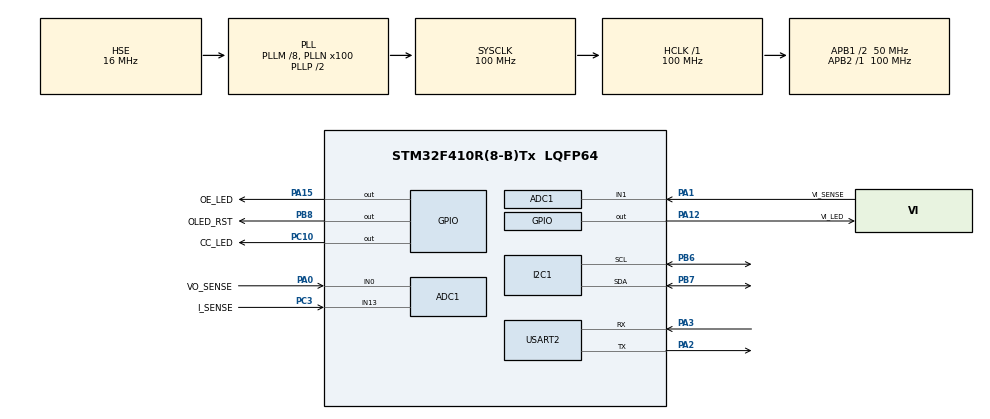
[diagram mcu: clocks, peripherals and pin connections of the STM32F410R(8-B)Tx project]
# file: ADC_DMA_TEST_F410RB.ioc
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Mcu.Family=STM32F4
VP_SYS_VS_tim6.Mode=TIM6
RCC.CortexFreq_Value=100000000
NVIC.TIM6_DAC_IRQn=true\:0\:0\:false\:false\:true\:false\:true
PC10.Signal=GPIO_Output
RCC.SYSCLKSource=RCC_SYSCLKSOURCE_PLLCLK
ProjectManager.StackSize=0x400
PA15.GPIO_Label=OE_LED
PA12.Signal=GPIO_Output
PH0\ -\ OSC_IN.Signal=RCC_OSC_IN
RCC.HCLKFreq_Value=100000000
RCC.APB2TimFreq_Value=100000000
PB6.Signal=I2C1_SCL
Dma.ADC1.0.Direction=DMA_PERIPH_TO_MEMORY
ADC1.Channel-2\#ChannelRegularConversion=ADC_CHANNEL_1
PB6.Mode=I2C
PC3.Signal=SharedAnalog_PC3
NVIC.DMA2_Stream0_IRQn=true\:0\:0\:false\:false\:true\:false\:true
Dma.ADC1.0.MemDataAlignment=DMA_MDATAALIGN_HALFWORD
RCC.AHBFreq_Value=100000000
ADC1.Channel-0\#ChannelRegularConversion=ADC_CHANNEL_13
RCC.HSE_VALUE=16000000
PB3.Mode=Trace_Asynchronous_SW
ADC1.Rank-2\#ChannelRegularConversion=3
PA14.Mode=Trace_Asynchronous_SW
Dma.ADC1.0.PeriphInc=DMA_PINC_DISABLE
PB8.PinState=GPIO_PIN_RESET
PB7.Signal=I2C1_SDA
ADC1.SamplingTime-0\#ChannelRegularConversion=ADC_SAMPLETIME_3CYCLES
Mcu.Package=LQFP64
NVIC.TimeBase=TIM6_DAC_IRQn
USART2.VirtualMode=VM_ASYNC
RCC.EnbaleCSS=true
NVIC.TimeBaseIP=TIM6
PA15.Signal=GPIO_Output
RCC.APB1TimFreq_Value=100000000
Dma.ADC1.0.FIFOMode=DMA_FIFOMODE_DISABLE
Dma.Request0=ADC1
ADC1.EOCSelection=ADC_EOC_SEQ_CONV
PA3.Signal=USART2_RX
RCC.PLLSourceVirtual=RCC_PLLSOURCE_HSE
Dma.ADC1.0.Instance=DMA2_Stream0
ADC1.Rank-0\#ChannelRegularConversion=1
PC10.GPIO_Label=CC_LED
SH.SharedAnalog_PC3.1=ADC1_IN13,IN13
SH.SharedAnalog_PA0.0=GPIO_Analog
SH.SharedAnalog_PC3.0=GPIO_Analog
SH.SharedAnalog_PA0.1=ADC1_IN0,IN0
PH1\ -\ OSC_OUT.Mode=HSE-External-Oscillator
TIM11.Prescaler=8400-1
RCC.APB1CLKDivider=RCC_HCLK_DIV2
PA12.GPIO_Label=VI_LED
ADC1.SamplingTime-2\#ChannelRegularConversion=ADC_SAMPLETIME_3CYCLES
PA0-WKUP.GPIO_Label=VO_SENSE
PA0-WKUP.Signal=SharedAnalog_PA0
VP_TIM11_VS_ClockSourceINT.Mode=Enable_Timer
PA13.Signal=SYS_JTMS-SWDIO
PA3.Mode=Asynchronous
PB8.GPIO_Label=OLED_RST
Dma.ADC1.0.PeriphDataAlignment=DMA_PDATAALIGN_HALFWORD
PH0\ -\ OSC_IN.Mode=HSE-External-Oscillator
ProjectManager.TargetToolchain=STM32CubeIDE
Dma.ADC1.0.Mode=DMA_CIRCULAR
I2C1.I2C_Mode=I2C_Fast
Dma.ADC1.0.Priority=DMA_PRIORITY_HIGH
ADC1.Channel-1\#ChannelRegularConversion=ADC_CHANNEL_0
RCC.LSE_VALUE=32768
PA1.Signal=SharedAnalog_PA1
PH1\ -\ OSC_OUT.Signal=RCC_OSC_OUT
board=custom
RCC.VCOOutputFreq_Value=200000000
RCC.APB2Freq_Value=100000000
PA1.GPIO_Label=VI_SENSE
ADC1.DMAContinuousRequests=ENABLE
ADC1.NbrOfConversion=3
PA13.Mode=Trace_Asynchronous_SW
Mcu.Name=STM32F410R(8-B)Tx
PA2.Signal=USART2_TX
RCC.48MHZClocksFreq_Value=50000000
PB3.Signal=SYS_JTDO-SWO
ADC1.SamplingTime-1\#ChannelRegularConversion=ADC_SAMPLETIME_3CYCLES
RCC.SYSCLKFreq_VALUE=100000000
ADC1.master=1
ADC1.Rank-1\#ChannelRegularConversion=2
PB7.Mode=I2C
PA14.Signal=SYS_JTCK-SWCLK
Dma.ADC1.0.MemInc=DMA_MINC_ENABLE
ProjectManager.HeapSize=0x200
RCC.HSI_VALUE=16000000
SH.SharedAnalog_PA1.1=ADC1_IN1,IN1
NVIC.PriorityGroup=NVIC_PRIORITYGROUP_4
SH.SharedAnalog_PA1.0=GPIO_Analog
ADC1.NbrOfConversionFlag=1
RCC.PLLM=8
RCC.PLLN=100
PA2.Mode=Asynchronous
PB8.Signal=GPIO_Output
PC3.GPIO_Label=I_SENSE
RCC.APB1Freq_Value=50000000

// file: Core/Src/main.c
/* USER CODE BEGIN Header */
/**
  ******************************************************************************
  * @file           : main.c
  * @brief          : Main program body
  ******************************************************************************
  * @attention
  *
  * <h2><center>&copy; Copyright (c) 2021 STMicroelectronics.
  * All rights reserved.</center></h2>
  *
  * This software component is licensed by ST under Ultimate Liberty license
  * SLA0044, the "License"; You may not use this file except in compliance with
  * the License. You may obtain a copy of the License at:
  *                             www.st.com/SLA0044
  *
  ******************************************************************************
  */
/* USER CODE END Header */
#include "main.h"

ADC_HandleTypeDef hadc1;
DMA_HandleTypeDef hdma_adc1;

I2C_HandleTypeDef hi2c1;

TIM_HandleTypeDef htim11;

UART_HandleTypeDef huart2;

/* USER CODE BEGIN PV */
uint16_t buff[3];
/* USER CODE END PV */

void SystemClock_Config(void);
static void MX_GPIO_Init(void);
static void MX_DMA_Init(void);
static void MX_ADC1_Init(void);
static void MX_I2C1_Init(void);
static void MX_TIM11_Init(void);
static void MX_USART2_UART_Init(void);

int main(void)
{

  /* MCU Configuration--------------------------------------------------------*/

  /* Reset of all peripherals, Initializes the Flash interface and the Systick. */
  HAL_Init();

  /* Configure the system clock */
  SystemClock_Config();

  /* Initialize all configured peripherals */
  MX_GPIO_Init();
  MX_DMA_Init();
  MX_ADC1_Init();
  MX_I2C1_Init();
  MX_TIM11_Init();
  MX_USART2_UART_Init();
  /* USER CODE BEGIN 2 */
  HAL_ADC_Start_DMA(&hadc1, (uint32_t *)buff, 3);
  /* USER CODE END 2 */

  /* Infinite loop */
  while (1)
  {

  }
}

void SystemClock_Config(void)
{
  RCC_OscInitTypeDef RCC_OscInitStruct = {0};
  RCC_ClkInitTypeDef RCC_ClkInitStruct = {0};

  /** Configure the main internal regulator output voltage
  */
  __HAL_RCC_PWR_CLK_ENABLE();
  __HAL_PWR_VOLTAGESCALING_CONFIG(PWR_REGULATOR_VOLTAGE_SCALE1);
  /** Initializes the RCC Oscillators according to the specified parameters
  * in the RCC_OscInitTypeDef structure.
  */
  RCC_OscInitStruct.OscillatorType = RCC_OSCILLATORTYPE_HSE;
  RCC_OscInitStruct.HSEState = RCC_HSE_ON;
  RCC_OscInitStruct.PLL.PLLState = RCC_PLL_ON;
  RCC_OscInitStruct.PLL.PLLSource = RCC_PLLSOURCE_HSE;
  RCC_OscInitStruct.PLL.PLLM = 8;
  RCC_OscInitStruct.PLL.PLLN = 100;
  RCC_OscInitStruct.PLL.PLLP = RCC_PLLP_DIV2;
  RCC_OscInitStruct.PLL.PLLQ = 4;
  RCC_OscInitStruct.PLL.PLLR = 2;
  if (HAL_RCC_OscConfig(&RCC_OscInitStruct) != HAL_OK)
  {
    Error_Handler();
  }
  /** Initializes the CPU, AHB and APB buses clocks
  */
  RCC_ClkInitStruct.ClockType = RCC_CLOCKTYPE_HCLK|RCC_CLOCKTYPE_SYSCLK
                              |RCC_CLOCKTYPE_PCLK1|RCC_CLOCKTYPE_PCLK2;
  RCC_ClkInitStruct.SYSCLKSource = RCC_SYSCLKSOURCE_PLLCLK;
  RCC_ClkInitStruct.AHBCLKDivider = RCC_SYSCLK_DIV1;
  RCC_ClkInitStruct.APB1CLKDivider = RCC_HCLK_DIV2;
  RCC_ClkInitStruct.APB2CLKDivider = RCC_HCLK_DIV1;

  if (HAL_RCC_ClockConfig(&RCC_ClkInitStruct, FLASH_LATENCY_3) != HAL_OK)
  {
    Error_Handler();
  }
  /** Enables the Clock Security System
  */
  HAL_RCC_EnableCSS();
}

static void MX_ADC1_Init(void)
{

  ADC_ChannelConfTypeDef sConfig = {0};

  /** Configure the global features of the ADC (Clock, Resolution, Data Alignment and number of conversion)
  */
  hadc1.Instance = ADC1;
  hadc1.Init.ClockPrescaler = ADC_CLOCK_SYNC_PCLK_DIV4;
  hadc1.Init.Resolution = ADC_RESOLUTION_12B;
  hadc1.Init.ScanConvMode = ENABLE;
  hadc1.Init.ContinuousConvMode = DISABLE;
  hadc1.Init.DiscontinuousConvMode = DISABLE;
  hadc1.Init.ExternalTrigConvEdge = ADC_EXTERNALTRIGCONVEDGE_NONE;
  hadc1.Init.ExternalTrigConv = ADC_SOFTWARE_START;
  hadc1.Init.DataAlign = ADC_DATAALIGN_RIGHT;
  hadc1.Init.NbrOfConversion = 3;
  hadc1.Init.DMAContinuousRequests = ENABLE;
  hadc1.Init.EOCSelection = ADC_EOC_SEQ_CONV;
  if (HAL_ADC_Init(&hadc1) != HAL_OK)
  {
    Error_Handler();
  }
  /** Configure for the selected ADC regular channel its corresponding rank in the sequencer and its sample time.
  */
  sConfig.Channel = ADC_CHANNEL_13;
  sConfig.Rank = 1;
  sConfig.SamplingTime = ADC_SAMPLETIME_3CYCLES;
  if (HAL_ADC_ConfigChannel(&hadc1, &sConfig) != HAL_OK)
  {
    Error_Handler();
  }
  /** Configure for the selected ADC regular channel its corresponding rank in the sequencer and its sample time.
  */
  sConfig.Channel = ADC_CHANNEL_0;
  sConfig.Rank = 2;
  if (HAL_ADC_ConfigChannel(&hadc1, &sConfig) != HAL_OK)
  {
    Error_Handler();
  }
  /** Configure for the selected ADC regular channel its corresponding rank in the sequencer and its sample time.
  */
  sConfig.Channel = ADC_CHANNEL_1;
  sConfig.Rank = 3;
  if (HAL_ADC_ConfigChannel(&hadc1, &sConfig) != HAL_OK)
  {
    Error_Handler();
  }

}

static void MX_I2C1_Init(void)
{

  hi2c1.Instance = I2C1;
  hi2c1.Init.ClockSpeed = 400000;
  hi2c1.Init.DutyCycle = I2C_DUTYCYCLE_2;
  hi2c1.Init.OwnAddress1 = 0;
  hi2c1.Init.AddressingMode = I2C_ADDRESSINGMODE_7BIT;
  hi2c1.Init.DualAddressMode = I2C_DUALADDRESS_DISABLE;
  hi2c1.Init.OwnAddress2 = 0;
  hi2c1.Init.GeneralCallMode = I2C_GENERALCALL_DISABLE;
  hi2c1.Init.NoStretchMode = I2C_NOSTRETCH_DISABLE;
  if (HAL_I2C_Init(&hi2c1) != HAL_OK)
  {
    Error_Handler();
  }

}

static void MX_TIM11_Init(void)
{

  htim11.Instance = TIM11;
  htim11.Init.Prescaler = 8400-1;
  htim11.Init.CounterMode = TIM_COUNTERMODE_UP;
  htim11.Init.Period = 65535;
  htim11.Init.ClockDivision = TIM_CLOCKDIVISION_DIV1;
  htim11.Init.AutoReloadPreload = TIM_AUTORELOAD_PRELOAD_DISABLE;
  if (HAL_TIM_Base_Init(&htim11) != HAL_OK)
  {
    Error_Handler();
  }

}

static void MX_USART2_UART_Init(void)
{

  huart2.Instance = USART2;
  huart2.Init.BaudRate = 115200;
  huart2.Init.WordLength = UART_WORDLENGTH_8B;
  huart2.Init.StopBits = UART_STOPBITS_1;
  huart2.Init.Parity = UART_PARITY_NONE;
  huart2.Init.Mode = UART_MODE_TX_RX;
  huart2.Init.HwFlowCtl = UART_HWCONTROL_NONE;
  huart2.Init.OverSampling = UART_OVERSAMPLING_16;
  if (HAL_UART_Init(&huart2) != HAL_OK)
  {
    Error_Handler();
  }

}

static void MX_DMA_Init(void)
{

  /* DMA controller clock enable */
  __HAL_RCC_DMA2_CLK_ENABLE();

  /* DMA interrupt init */
  /* DMA2_Stream0_IRQn interrupt configuration */
  HAL_NVIC_SetPriority(DMA2_Stream0_IRQn, 0, 0);
  HAL_NVIC_EnableIRQ(DMA2_Stream0_IRQn);

}

static void MX_GPIO_Init(void)
{
  GPIO_InitTypeDef GPIO_InitStruct = {0};

  /* GPIO Ports Clock Enable */
  __HAL_RCC_GPIOH_CLK_ENABLE();
  __HAL_RCC_GPIOC_CLK_ENABLE();
  __HAL_RCC_GPIOA_CLK_ENABLE();
  __HAL_RCC_GPIOB_CLK_ENABLE();

  /*Configure GPIO pin Output Level */
  HAL_GPIO_WritePin(GPIOA, VI_LED_Pin|OE_LED_Pin, GPIO_PIN_RESET);

  /*Configure GPIO pin Output Level */
  HAL_GPIO_WritePin(CC_LED_GPIO_Port, CC_LED_Pin, GPIO_PIN_RESET);

  /*Configure GPIO pin Output Level */
  HAL_GPIO_WritePin(OLED_RST_GPIO_Port, OLED_RST_Pin, GPIO_PIN_RESET);

  /*Configure GPIO pins : VI_LED_Pin OE_LED_Pin */
  GPIO_InitStruct.Pin = VI_LED_Pin|OE_LED_Pin;
  GPIO_InitStruct.Mode = GPIO_MODE_OUTPUT_PP;
  GPIO_InitStruct.Pull = GPIO_NOPULL;
  GPIO_InitStruct.Speed = GPIO_SPEED_FREQ_LOW;
  HAL_GPIO_Init(GPIOA, &GPIO_InitStruct);

  /*Configure GPIO pin : CC_LED_Pin */
  GPIO_InitStruct.Pin = CC_LED_Pin;
  GPIO_InitStruct.Mode = GPIO_MODE_OUTPUT_PP;
  GPIO_InitStruct.Pull = GPIO_NOPULL;
  GPIO_InitStruct.Speed = GPIO_SPEED_FREQ_LOW;
  HAL_GPIO_Init(CC_LED_GPIO_Port, &GPIO_InitStruct);

  /*Configure GPIO pin : OLED_RST_Pin */
  GPIO_InitStruct.Pin = OLED_RST_Pin;
  GPIO_InitStruct.Mode = GPIO_MODE_OUTPUT_PP;
  GPIO_InitStruct.Pull = GPIO_NOPULL;
  GPIO_InitStruct.Speed = GPIO_SPEED_FREQ_LOW;
  HAL_GPIO_Init(OLED_RST_GPIO_Port, &GPIO_InitStruct);

}

 /**
  * @brief  Period elapsed callback in non blocking mode
  * @note   This function is called  when TIM6 interrupt took place, inside
  * HAL_TIM_IRQHandler(). It makes a direct call to HAL_IncTick() to increment
  * a global variable "uwTick" used as application time base.
  * @param  htim : TIM handle
  * @retval None
  */
void HAL_TIM_PeriodElapsedCallback(TIM_HandleTypeDef *htim)
{
  if (htim->Instance == TIM6) {
    HAL_IncTick();
  }
}

void Error_Handler(void)
{
  __disable_irq();
  while (1)
  {
  }
}

/************************ (C) COPYRIGHT STMicroelectronics *****END OF FILE****/
